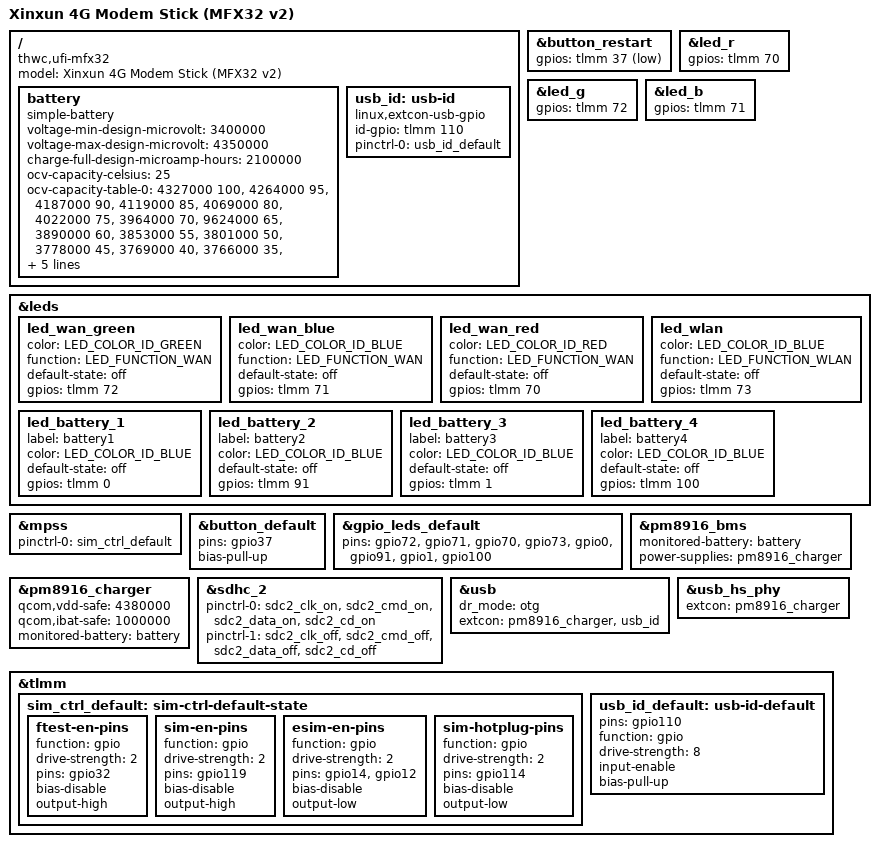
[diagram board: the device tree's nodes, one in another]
// SPDX-License-Identifier: GPL-2.0-only

/dts-v1/;

#include "msm8916-ufi.dtsi"

/ {
	model = "Xinxun 4G Modem Stick (MFX32 v2)";
	compatible = "thwc,ufi-mfx32", "qcom,msm8916";

	battery: battery {
		compatible = "simple-battery";
		voltage-min-design-microvolt = <3400000>;
		voltage-max-design-microvolt = <4350000>;
		charge-full-design-microamp-hours = <2100000>;

		ocv-capacity-celsius = <25>;
		ocv-capacity-table-0 = < 4327000 100 >,
							   < 4264000 95 >,
							   < 4187000 90 >,
							   < 4119000 85 >,
							   < 4069000 80 >,
							   < 4022000 75 >,
							   < 3964000 70 >,
							   < 9624000 65 >,
							   < 3890000 60 >,
							   < 3853000 55 >,
							   < 3801000 50 >,
							   < 3778000 45 >,
							   < 3769000 40 >,
							   < 3766000 35 >,
							   < 3760000 30 >,
							   < 3721000 25 >,
							   < 3660000 20 >,
							   < 3608000 16 >,
							   < 3579000 13 >,
							   < 3563000 11 >,
							   < 3548000 10 >,
							   < 3531000 9 >,
							   < 3520000 8 >,
							   < 3514000 7 >,
							   < 3502000 6 >,
							   < 3495000 5 >,
							   < 3489000 4 >,
							   < 3475000 3 >,
							   < 3460000 2 >,
							   < 3444000 1 >,
							   < 3400000 0 >;
	};

	usb_id: usb-id {
		compatible = "linux,extcon-usb-gpio";
		id-gpio = <&tlmm 110 GPIO_ACTIVE_HIGH>;
		pinctrl-names = "default";
		pinctrl-0 = <&usb_id_default>;
	};
};

&button_restart {
	gpios = <&tlmm 37 GPIO_ACTIVE_LOW>;
};

&led_r {
	gpios = <&tlmm 70 GPIO_ACTIVE_HIGH>;
};

&led_g {
	gpios = <&tlmm 72 GPIO_ACTIVE_HIGH>;
};

&led_b {
	gpios = <&tlmm 71 GPIO_ACTIVE_HIGH>;
};

&leds {
	led_wan_green {
		color = <LED_COLOR_ID_GREEN>;
		function = LED_FUNCTION_WAN;
		default-state = "off";
		gpios = <&tlmm 72 GPIO_ACTIVE_HIGH>;
	};

	led_wan_blue {
		color = <LED_COLOR_ID_BLUE>;
		function = LED_FUNCTION_WAN;
		default-state = "off";
		gpios = <&tlmm 71 GPIO_ACTIVE_HIGH>;
	};

	led_wan_red {
		color = <LED_COLOR_ID_RED>;
		function = LED_FUNCTION_WAN;
		default-state = "off";
		gpios = <&tlmm 70 GPIO_ACTIVE_HIGH>;
	};

	led_wlan {
		color = <LED_COLOR_ID_BLUE>;
		function = LED_FUNCTION_WLAN;
		default-state = "off";
		gpios = <&tlmm 73 GPIO_ACTIVE_HIGH>;
	};

	led_battery_1 {
		label = "battery1";
		color = <LED_COLOR_ID_BLUE>;
		default-state = "off";
		gpios = <&tlmm 0 GPIO_ACTIVE_HIGH>;
	};

	led_battery_2 {
		label = "battery2";
		color = <LED_COLOR_ID_BLUE>;
		default-state = "off";
		gpios = <&tlmm 91 GPIO_ACTIVE_HIGH>;
	};

	led_battery_3 {
		label = "battery3";
		color = <LED_COLOR_ID_BLUE>;
		default-state = "off";
		gpios = <&tlmm 1 GPIO_ACTIVE_HIGH>;
	};

	led_battery_4 {
		label = "battery4";
		color = <LED_COLOR_ID_BLUE>;
		default-state = "off";
		gpios = <&tlmm 100 GPIO_ACTIVE_HIGH>;
	};
};

&mpss {
	pinctrl-0 = <&sim_ctrl_default>;
	pinctrl-names = "default";
};

&button_default {
	pins = "gpio37";
	bias-pull-up;
};

&gpio_leds_default {
	pins = "gpio72", "gpio71", "gpio70", "gpio73", "gpio0", "gpio91", "gpio1", "gpio100";
};

&pm8916_bms {
	status = "okay";

	monitored-battery = <&battery>;
	power-supplies = <&pm8916_charger>;
};

&pm8916_charger {
	status = "okay";

	qcom,vdd-safe = <4380000>;
	qcom,ibat-safe = <1000000>;

	monitored-battery = <&battery>;
};

&sdhc_2 {
	status = "okay";

	pinctrl-names = "default", "sleep";
	pinctrl-0 = <&sdc2_clk_on &sdc2_cmd_on &sdc2_data_on &sdc2_cd_on>;
	pinctrl-1 = <&sdc2_clk_off &sdc2_cmd_off &sdc2_data_off &sdc2_cd_off>;
};

&usb {
	dr_mode = "otg";
	extcon = <&pm8916_charger>, <&usb_id>;
};

&usb_hs_phy {
	extcon = <&pm8916_charger>;
};

/* This selects the external SIM card slot by default */
&tlmm {
	sim_ctrl_default: sim-ctrl-default-state {

		ftest-en-pins {
			function = "gpio";
			drive-strength = <2>;
			pins = "gpio32";
			bias-disable;
			output-high;
		};

		sim-en-pins {
			function = "gpio";
			drive-strength = <2>;
			pins = "gpio119";
			bias-disable;
			output-high;
		};

		esim-en-pins {
			function = "gpio";
			drive-strength = <2>;
			pins = "gpio14", "gpio12";
			bias-disable;
			output-low;
		};

		sim-hotplug-pins {
			function = "gpio";
			drive-strength = <2>;
			pins = "gpio114";
			bias-disable;
			output-low;
		};
	};

	usb_id_default: usb-id-default {
		pins = "gpio110";
		function = "gpio";

		drive-strength = <8>;
		input-enable;
		bias-pull-up;
	};
};
